# platform_designer_hps_system_hps_0_hps register map
Vendor: default_vendor.com; File version: 0.0
Registers are 32-bit, read-write, reset 0x0 unless marked. A register's access mark holds for its fields unless they carry their own. Offsets are from the block's base; [hi:lo] are bit positions; 'fields as' and 'values as' point back to an identical list.

## lwhps2fpgaregs — Registers in the LWHPS2FPGA AXI Bridge Module.
Base 0xFF400000
0x1FD0 idgrp_periph_id_4 ro reset 0x4 — JEP106 continuation code
  [7:0] periph_id_4
0x1FE0 idgrp_periph_id_0 ro reset 0x1 — Peripheral ID0
  [7:0] pn7to0 — Part Number [7:0]
0x1FE4 idgrp_periph_id_1 ro reset 0xB3 — Peripheral ID1
  [7:0] jep3to0_pn11to8 — JEP106[3:0], Part Number [11:8]
0x1FE8 idgrp_periph_id_2 ro reset 0x6B — Peripheral ID2
  [7:0] rev_jepcode_jep6to4 — Revision, JEP106 code flag, JEP106[6:4]
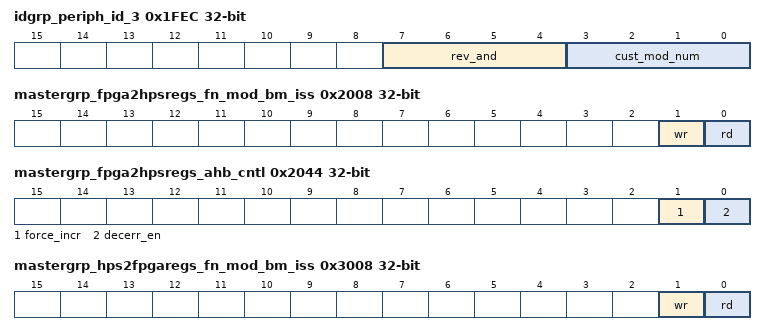
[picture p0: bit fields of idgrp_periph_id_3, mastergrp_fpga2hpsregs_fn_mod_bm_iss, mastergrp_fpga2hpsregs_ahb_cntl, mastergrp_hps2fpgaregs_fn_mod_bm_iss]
0x1FEC idgrp_periph_id_3 ro — Peripheral ID3
  [7:4] rev_and — Revision
  [3:0] cust_mod_num — Customer Model Number
0x1FF0 idgrp_comp_id_0 ro reset 0xD — Component ID0
  [7:0] preamble
0x1FF4 idgrp_comp_id_1 ro reset 0xF0 — Component ID1
  [7:0] genipcompcls_preamble — Generic IP component class, Preamble
0x1FF8 idgrp_comp_id_2 ro reset 0x5 — Component ID2
  [7:0] preamble
0x1FFC idgrp_comp_id_3 ro reset 0xB1 — Component ID3
  [7:0] preamble
0x2008 mastergrp_fpga2hpsregs_fn_mod_bm_iss — Sets the issuing capability of the preceding switch arbitration scheme to multiple or single outstanding transactions.
  [1] wr
    0=multiple; 1=single
  [0] rd
    0=multiple; 1=single
0x2044 mastergrp_fpga2hpsregs_ahb_cntl — Sets the block issuing capability to one outstanding transaction.
  [1] force_incr
    0=disable; 1=enable
  [0] decerr_en
    0=disable; 1=enable
0x3008 mastergrp_hps2fpgaregs_fn_mod_bm_iss — Sets the issuing capability of the preceding switch arbitration scheme to multiple or single outstanding transactions.
  [1] wr
    0=multiple; 1=single
  [0] rd
    0=multiple; 1=single
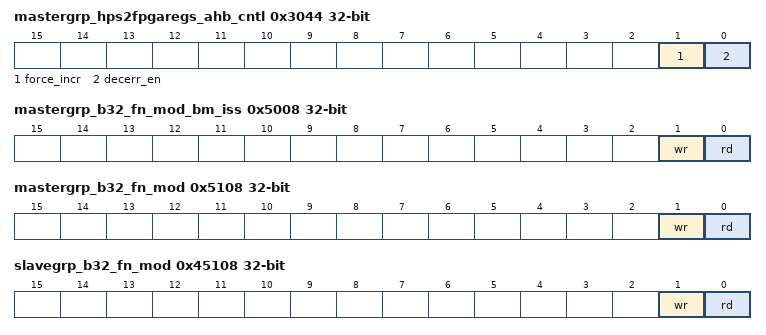
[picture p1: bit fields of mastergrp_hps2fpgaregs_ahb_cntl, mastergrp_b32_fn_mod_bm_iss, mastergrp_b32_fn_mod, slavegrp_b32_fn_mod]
0x3044 mastergrp_hps2fpgaregs_ahb_cntl — Sets the block issuing capability to one outstanding transaction.
  fields as mastergrp_fpga2hpsregs_ahb_cntl
0x5008 mastergrp_b32_fn_mod_bm_iss — Sets the issuing capability of the preceding switch arbitration scheme to multiple or single outstanding transactions.
  [1] wr
    0=multiple; 1=single
  [0] rd
    0=multiple; 1=single
0x5040 mastergrp_b32_wr_tidemark reset 0x4 — Controls the release of the transaction in the write data FIFO.
  [3:0] level — Stalls the transaction in the write data FIFO until the number of occupied slots in the write data FIFO exceeds the level. Note that the transaction is released before this level is achieved if the network receives the WLAST beat or the write FIFO becomes full.
0x5108 mastergrp_b32_fn_mod — Sets the block issuing capability to multiple or single outstanding transactions.
  [1] wr
    0=multiple; 1=single
  [0] rd
    0=multiple; 1=single
0x45108 slavegrp_b32_fn_mod — Sets the block issuing capability to multiple or single outstanding transactions.
  [1] wr
    0=multiple; 1=single
  [0] rd
    0=multiple; 1=single

## hps2fpgaregs — Registers in the HPS2FPGA AXI Bridge Module.
Base 0xFF500000
Registers as lwhps2fpgaregs, without mastergrp_fpga2hpsregs_fn_mod_bm_iss, mastergrp_fpga2hpsregs_ahb_cntl, mastergrp_hps2fpgaregs_fn_mod_bm_iss, mastergrp_hps2fpgaregs_ahb_cntl, mastergrp_b32_fn_mod_bm_iss, mastergrp_b32_wr_tidemark, mastergrp_b32_fn_mod, slavegrp_b32_fn_mod; these are added or differ:
0x2024 mastergrp_b32_fn_mod2 — Controls bypass merge of upsizing/downsizing.
  [0] bypass_merge
    0=alter; 1=noalter
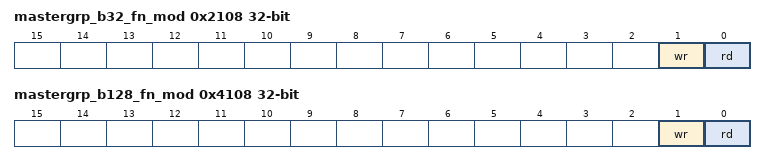
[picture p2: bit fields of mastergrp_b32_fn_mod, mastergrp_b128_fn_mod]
0x2108 mastergrp_b32_fn_mod — Sets the block issuing capability to multiple or single outstanding transactions.
  [1] wr
    0=multiple; 1=single
  [0] rd
    0=multiple; 1=single
0x4024 mastergrp_b128_fn_mod2 — Controls bypass merge of upsizing/downsizing.
  [0] bypass_merge
    0=alter; 1=noalter
0x4108 mastergrp_b128_fn_mod — Sets the block issuing capability to multiple or single outstanding transactions.
  [1] wr
    0=multiple; 1=single
  [0] rd
    0=multiple; 1=single

## fpga2hpsregs — Registers in the FPGA2HPS AXI Bridge Module.
Base 0xFF600000
Registers as lwhps2fpgaregs, without mastergrp_fpga2hpsregs_fn_mod_bm_iss, mastergrp_fpga2hpsregs_ahb_cntl, mastergrp_hps2fpgaregs_fn_mod_bm_iss, mastergrp_hps2fpgaregs_ahb_cntl, mastergrp_b32_fn_mod_bm_iss, mastergrp_b32_wr_tidemark, mastergrp_b32_fn_mod, slavegrp_b32_fn_mod; these are added or differ:
0x42024 slavegrp_b32_fn_mod2 — Controls bypass merge of upsizing/downsizing.
  [0] bypass_merge
    0=alter; 1=noalter
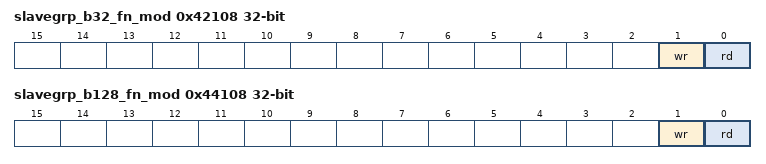
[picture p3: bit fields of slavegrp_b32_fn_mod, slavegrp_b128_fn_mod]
0x42108 slavegrp_b32_fn_mod — Sets the block issuing capability to multiple or single outstanding transactions.
  [1] wr
    0=multiple; 1=single
  [0] rd
    0=multiple; 1=single
0x44024 slavegrp_b128_fn_mod2 — Controls bypass merge of upsizing/downsizing.
  [0] bypass_merge
    0=alter; 1=noalter
0x44108 slavegrp_b128_fn_mod — Sets the block issuing capability to multiple or single outstanding transactions.
  [1] wr
    0=multiple; 1=single
  [0] rd
    0=multiple; 1=single
